# CY8C4245AXI_483 register map
File version: 0.1
PSoC 4200
Registers are 32-bit, read-write, no defined reset value unless marked. A register's access mark holds for its fields unless they carry their own. Offsets are from the block's base; lines under a group give offsets from that group; [hi:lo] are bit positions; {n}, {i} and the like mark numbered series; 'fields as' and 'values as' point back to an identical list; <NAME> marks a mode.

## Memory map
0x00000000 UpDown
0x00000000 Transimpedance — OpAmp
0x00000000 ADC_SAR_SEQ — Sequencing SAR ADC
0x00000000 I2CMaster — Serial Communication Block
0x00000000 QuadDec_1
0x00000000 PWM_1
0x00000000 ROSSerial_UART — Serial Communication Block
0x00000000 CapSense_IDAC1 — IDAC
0x00000000 CapSense_IDAC2 — IDAC
0x400F0072 Stepper_Control

## Stepper_Control
Base 0x400F0072
0x00 Stepper_Control_CONTROL_REG 8-bit

## UpDown
Base 0x00000000
0x400F0000 UpDown_COUNTER — UDB.A0 - Current Counter Value
0x400F0020 UpDown_PERIOD — UDB.D0 - Assigned Period
0x400F0030 UpDown_COMPARE — UDB.D1 - Assigned Compare Value
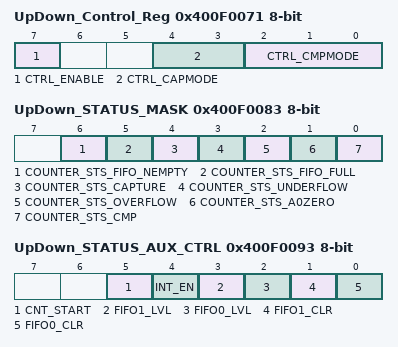
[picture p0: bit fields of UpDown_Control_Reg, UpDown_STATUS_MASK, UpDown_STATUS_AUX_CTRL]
0x400F0071 UpDown_Control_Reg 8-bit — UDB Control Register - Assigned Control Register Value
  [7] CTRL_ENABLE — Enable Counter
  [4:3] CTRL_CAPMODE — Capture mode
  [2:0] CTRL_CMPMODE — Compare mode
0x400F0083 UpDown_STATUS_MASK 8-bit — UDB Status bits Interrupt Mask Enable Register
  [6] COUNTER_STS_FIFO_NEMPTY — FIFO Not Empty Status
  [5] COUNTER_STS_FIFO_FULL — FIFO Full Status
  [4] COUNTER_STS_CAPTURE — Capture Status
  [3] COUNTER_STS_UNDERFLOW — Underflow status
  [2] COUNTER_STS_OVERFLOW — Overflow status
  [1] COUNTER_STS_A0ZERO — A0 Zero ouput status
  [0] COUNTER_STS_CMP — Compare output status
0x400F0093 UpDown_STATUS_AUX_CTRL 8-bit — UDB Auxilliary Control Register
  [5] CNT_START — FIFO0 clear
    0=E_CNT_START0 (Disable counter); 1=E_CNT_START1 (Enable counter)
  [4] INT_EN
    0=E_INT_EN0 (Interrupt disabled); 1=E_INT_EN1 (Interrupt enabled)
  [3] FIFO1_LVL — FIFO level
    0=E_FIFO_LVL_0 (FIFO LVL: input mode: FIFO not full; output mode: FIFO not empty); 1=E_FIFO_LVL_1 (FIFO LVL: input mode: FIFO at least 1/2 empty; output mode: FIFO at least 1/2 full)
  [2] FIFO0_LVL — FIFO level
    values as FIFO1_LVL
  [1] FIFO1_CLR — FIFO1 clear
    0=E_FIFO_CLR_0 (Normal FIFO operation); 1=E_FIFO_CLR_1 (Clear FIFO state)
  [0] FIFO0_CLR — FIFO0 clear
    values as FIFO1_CLR

## Transimpedance — OpAmp
Base 0x00000000
0x40100000 CONTROL — Opamp control
0x40100004 RES_CONTROL — Opamp resistor control
0x4010000C STATUS — Opamp status
0x40100F00 OFFSET_TRIM — Opamp offset trim
0x40100F04 SLOPE_OFFSET_TRIM — Opamp slope offset trim
0x40100F08 TRIM — Opamp trim

## QuadDec_1
Base 0x00000000
0x40050108 COUNTER — Current counter value
0x4005010C CC — Compare / capture value
0x40050110 CC_BUF — Compare / capture buffer value
0x40050114 PERIOD — Period value
0x40050118 PERIOD_BUF — Period buffer value

## PWM_1
Base 0x00000000
0x40050148 COUNTER — Current counter value
0x4005014C CC — Compare / capture value
0x40050150 CC_BUF — Compare / capture buffer value
0x40050154 PERIOD — Period value
0x40050158 PERIOD_BUF — Period buffer value

## CapSense_IDAC1 — IDAC
Base 0x00000000
Same registers: CapSense_IDAC2 0x00000000
0x40080004 CSD_IDAC_POLARITY
0x40080008 CSD_IDAC
0x4008FF00 CSD_TRIM1 — CSD IDAC TRIM1
0x4008FF04 CSD_TRIM2 — CSD IDAC TRIM2
